# M5531 register map
File version: 1.0
Registers are 32-bit, read-write, reset 0x0 unless marked. A register's access mark holds for its fields unless they carry their own. Offsets are from the block's base; [hi:lo] are bit positions; {n}, {i} and the like mark numbered series; 'fields as' and 'values as' point back to an identical list.

## UTCPD — UTCPD Register Map
Base 0x4029B000
0x00 UTCPD_VID ro reset 0x416 — UTCPD Vendor ID Register
  [15:0] VID — UTCPD Vendor ID. Vendor identifier is used to identify the TCPC vendor, the VID is a unique 16-bit unsigned integer assigned by USB-IF to the Vendor.
0x04 UTCPD_PID (reset mask 0xFFFF0000) — UTCPD Product ID Register
  [15:0] PID — UTCPD Product ID. USB Product ID is used to identify the product
0x08 UTCPD_DID ro reset 0x1 — UTCPD Device ID Register
  [15:0] DID — UTCPD Device ID. USB Device ID is used to identify the release version of the product
0x0C UTCPD_TCREV ro reset 0x13 — UTCPD USB Type C Revision Register
  [7:0] TCREV — UTCPD USB Type C Revision. USB Type-C Cable and Connector Specification Revision 1.3
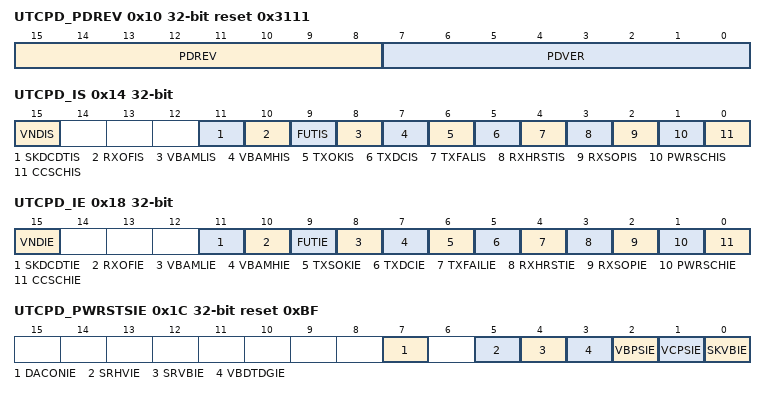
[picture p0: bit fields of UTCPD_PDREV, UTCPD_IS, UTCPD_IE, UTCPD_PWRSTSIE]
0x10 UTCPD_PDREV reset 0x3111 — UTCPD USB PD Revision Register
  [15:8] PDREV — UTCPD USB PD Revision. USB Power Delivery Specification revision 3.1
  [7:0] PDVER — UTCPD USB PD Vision. USB Power Delivery Specification Version 1.1
0x14 UTCPD_IS — UTCPD Interrupt Status Register
  [15] VNDIS — Vendor Define Event Detected. Note: It is cleared by software writing 1 into this bit.
    0=No vendor defined interrupt status has been detected; 1=A vendor defined interrupt status has been detected. Refer the vender defined interrupt status register
  [11] SKDCDTIS — VBUS Sink Disconnect Detected. This bit will be set when VBMONI (UTCPD_PWRCTL[6]) is enabled and VBUS voltage drop lower than SKVBDCTH (UTCPD_SKVBDCTH[9:0]). Note: It is cleared by software writing 1 into this bit.
    0=No disconnect detected; 1=A VBUS Sink disconnect threshold crossing has been detected
  [10] RXOFIS — Rx Buffer Overflow. Writing 1 to this register acknowledges the overflow. The overflow is cleared by writing 1 to RXSOPIS (UTCPD_IS[2])
    0=RX buffer is functioning properly; 1=RX buffer has overflowed
  [9] FUTIS — Fault Occur. Note: It is cleared by software writing 1 into this bit.
    0=No fault occurs; 1=A Fault has occurred. Read the FUT_STS register
  [8] VBAMLIS — VBUS Voltage Alarm Low. This bit will be set high when DSVBAM (UTCPD_PWRCTL[5]]) is low and VBUS voltage is lower than VBAML (UTCPD_VBAML[9:0]). Note: It is cleared by software writing 1 into this bit.
    0=No Low voltage alarm has occurred; 1=A Low voltage alarm has occurred
  [7] VBAMHIS — VBUS Voltage Alarm High. This bit will be set high when DSVBAM (UTCPD_PWRCTL[5]) is low and VBUS voltage is higher than VBAMH (UTCPD_VBAMH[9:0]). Note: It is cleared by software writing 1 into this bit.
    0=No high voltage alarm has occurred; 1=A high voltage alarm has occurred
  [6] TXOKIS — Transmit SOP* Message Successful. Note: It is cleared by software writing 1 into this bit.
    0=No TX SOP* transmit; 1=Reset or SOP* message transmission successful. GoodCRC response received on SOP* message transmission. Transmit SOP* message buffer registers are empty
  [5] TXDCIS — Transmit SOP* Message Discarded. Note: It is cleared by software writing 1 into this bit.
    0=No TX SOP discarded; 1=Reset or SOP* message transmission not sent due to incoming receive message. Transmit SOP* message buffer registers are empty
  [4] TXFALIS — Transmit SOP Fail. Note: It is cleared by software writing 1 into this bit.
    0=No Transmit SOP fail; 1=SOP* message transmission not successful, no GoodCRC response received on SOP* message transmission. Transmit SOP* message buffer registers are empty
  [3] RXHRSTIS — Received Hard Reset. Note: It is cleared by software writing 1 into this bit.
    0=No Hard reset Received; 1=Received Hard reset
  [2] RXSOPIS — Received SOP Message. UTCPD_RXBCNT being set to 0 does not set this bit. Note: It is cleared by software writing 1 into this bit.
    0=No SOP message Received; 1=Received SOP message
  [1] PWRSCHIS — Power Status Changed. Note: It is cleared by software writing 1 into this bit.
    0=Power status not change; 1=Power status changed
  [0] CCSCHIS — CC Status Changed. Note: It is cleared by software writing 1 into this bit.
    0=CC status not change; 1=CC status changed
0x18 UTCPD_IE — UTCPD Interrupt Enable Register
  [15] VNDIE — Vendor Define Event Detected Interrupt Enable
    0=Vendor define event detected interrupt Disabled; 1=Vendor define event detected interrup Enabled
  [11] SKDCDTIE — VBUS Sink Disconnect Detected Interrupt Enable
    0=VBUS Sink Disconnect Detected Interrupt Disabled; 1=VBUS Sink Disconnect Detected Interrupt Enabled
  [10] RXOFIE — Rx Buffer Overflow Interrupt Enable
    0=Rx Buffer Overflow Interrupt Disabled; 1=Rx Buffer Overflow Interrupt Enabled
  [9] FUTIE — Fault Occur Interrupt Enable
    0=Fault Occur Interrupt Disabled; 1=Fault Occur Interrupt Enabled
  [8] VBAMLIE — VBUS Voltage Alarm Low Interrupt Enable
    0=VBUS Voltage Alarm Low Interrupt Disabled; 1=VBUS Voltage Alarm Low Interrupt Enabled
  [7] VBAMHIE — VBUS Voltage Alarm High Interrupt Enable
    0=VBUS Voltage Alarm High Interrupt Disabled; 1=VBUS Voltage Alarm High Interrupt Enabled
  [6] TXSOKIE — Transmit SOP* Message Successful Interrupt Enable
    0=Transmit SOP* Message Successful Interrupt Disabled; 1=Transmit SOP* Message Successful Interrupt Enabled
  [5] TXDCIE — Transmit SOP* Message Discarded Interrupt Enable
    0=Transmit SOP* Message Discarded Interrupt Disabled; 1=Transmit SOP* Message Discarded Interrupt Enabled
  [4] TXFAILIE — Transmit SOP Fail Interrupt Enable
    0=Transmit SOP Fail Interrupt Disabled; 1=Transmit SOP Fail Interrupt Enabled
  [3] RXHRSTIE — Received Hard Reset Interrupt Enable
    0=Received Hard Reset Interrupt Disabled; 1=Received Hard Reset Interrupt Enabled
  [2] RXSOPIE — Received SOP Message Interrupt Enable
    0=Received SOP Message Interrupt Disabled; 1=Received SOP Message Interrupt Enabled
  [1] PWRSCHIE — Power Status Changed Interrupt Enable
    0=Power Status Changed Interrupt Disabled; 1=Power Status Changed Interrupt Enabled
  [0] CCSCHIE — CC Status Changed Interrupt Enable
    0=CC Status Changed Interrupt Disabled; 1=CC Status Changed Interrupt Enabled
0x1C UTCPD_PWRSTSIE reset 0xBF — UTCPD Power Status Interrupt Enable Register
  [7] DACONIE — Debug Accessory Connected Status Interrupt Enable
    0=Debug Accessory Connected Status Interrupt Disabled; 1=Debug Accessory Connected Status Interrupt Enabled
  [5] SRHVIE — Sourcing High Voltage Status Interrupt Enable
    0=Sourcing High Voltage Status Interrupt Disabled; 1=Sourcing High Voltage Status Interrupt Enabled
  [4] SRVBIE — Sourcing VBUS Status Interrupt Enable
    0=Sourcing VBUS Status Interrupt Disabled; 1=Sourcing VBUS Status Interrupt Enabled
  [3] VBDTDGIE — VBUS Detection Status Change Interrupt Enable
    0=VBUS Detection Status Change Interrupt Disabled; 1=VBUS Detection Status Change Interrupt Enabled
  [2] VBPSIE — VBUS Present Status Interrupt Enable
    0=VBUS Present Status Interrupt Disabled; 1=VBUS Present Status Interrupt Enabled
  [1] VCPSIE — VCONN Present Status Interrupt Enable
    0=VCONN Present Status Interrupt Disabled; 1=VCONN Present Status Interrupt Enabled
  [0] SKVBIE — Sinking VBUS Status Interrupt Enable
    0=Sinking VBUS Status Interrupt Disabled; 1=Sinking VBUS Status Interrupt Enabled
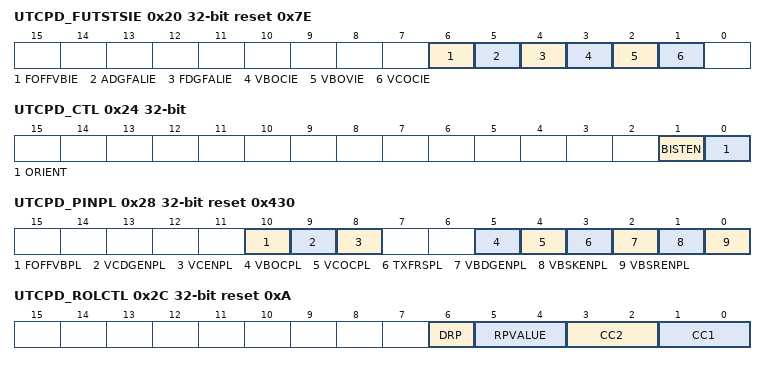
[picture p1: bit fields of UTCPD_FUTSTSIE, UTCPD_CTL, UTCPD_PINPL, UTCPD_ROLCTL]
0x20 UTCPD_FUTSTSIE reset 0x7E — UTCPD Fault Status Interrupt Enable Register
  [6] FOFFVBIE — Force Off VBUS Interrupt Enable
    0=Force Off VBUS Interrupt Disabled; 1=Force Off VBUS Interrupt Enabled
  [5] ADGFALIE — Auto Discharge Failed Interrupt Enable
    0=Auto Discharge Failed Interrupt Disabled; 1=Auto Discharge Failed Interrupt Enabled
  [4] FDGFALIE — Force Discharge Failed Interrupt Enable
    0=Force Discharge Failed Interrupt Disabled; 1=Force Discharge Failed Interrupt Enabled
  [3] VBOCIE — External VBUS OCP Fault Interrupt Enable
    0=External VBUS OCP Fault Interrupt Disabled; 1=External VBUS OCP Fault Interrupt Enabled
  [2] VBOVIE — Internal VBUS OVP Fault Interrupt Enable
    0=Internal VBUS OVP Fault Interrupt Disabled; 1=Internal VBUS OVP Fault Interrupt Enabled
  [1] VCOCIE — VCONN OCP Fault Interrupt Enable
    0=VCONN OCP Fault Interrupt Disabled; 1=VCONN OCP Fault Interrupt Enabled
0x24 UTCPD_CTL — UTCPD Control Register
  [1] BISTEN — BIST Test Mode. Setting this bit to 1 is intended to be used only when a USB compliance tester is using USB BIST Test Data to test the PHY layer of the UTCPD. The CPU should clear this bit when a detach is detected.
    0=Normal Operation; 1=BIST Test Mode
  [0] ORIENT — Plug Orientation communications if PD messaging is enabled.
    0=When VCONN is enabled, apply it to the CC2 pin. Monitor the CC1 pin for BMC communications if PD messaging is enabled; 1=When VCONN is enabled, apply it to the CC1 pin. Monitor the CC2 pin for BMC
0x28 UTCPD_PINPL reset 0x430 — UTCPD Pin Polarity Control Register
  [all] fields
    0=Low active; 1=High active
  [10] FOFFVBPL — Force Off VBUS event Polarity
  [9] VCDGENPL — VCONN Discharge Enable Polarity
  [8] VCENPL — VCONN Enable Polarity
  [5] VBOCPL — VBUS Overcurrent event Polarity
  [4] VCOCPL — VCONN Overcurrent event Polarity
  [3] TXFRSPL — Fast Role Swap TX Polarity
  [2] VBDGENPL — VBUS Discharge Enable Polarity. It is for Bleed Discharge Enable Polarity.
  [1] VBSKENPL — VBUS Sink Enable Polarity
  [0] VBSRENPL — VBUS Source Enable Polarity
0x2C UTCPD_ROLCTL reset 0xA — UTCPD Role Control Register
  [6] DRP — DRP. The UTCPD toggles CC1 CC2 after receiving LK4CON (UTCPD_CMD[5]) and until a connection is detected. Upon connection, the UTCPD shall resolve to either an Rp or Rd and report the CC1/CC2 State in the CC_STS register.
    0=No DRP; 1=DRP
  [5:4] RPVALUE
    0=Rp default; 1=Rp 1.5A; 2=Rp 3.0A
  [3:2] CC2
    1=Rp (Use Rp definition in RPVALUE); 2=Rd; 3=Open (Disconnect or don't care)
  [1:0] CC1
    2=Rd; 3=Open (Disconnect or don't care)
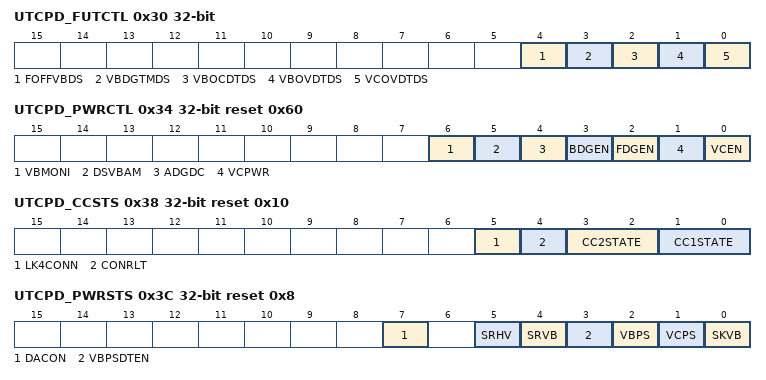
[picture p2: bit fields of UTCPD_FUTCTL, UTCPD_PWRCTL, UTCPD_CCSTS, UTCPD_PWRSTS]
0x30 UTCPD_FUTCTL — UTCPD Fault Control Register
  [4] FOFFVBDS — Force Off VBUS Disable
    0=Force off VBUS Enabled; 1=Force off VBUS Disabled
  [3] VBDGTMDS — VBUS Discharge Fault Detection Timer Disable. This enables the timer for both force discharge and auto discharge. No timer for bleed discharge. Once time-out, UTCPD will compare VBUS voltage with VSAFE0V or SP_DGTH, depends on setting of ADGDC and FDGEN.
    0=VBUS Discharge Fault Detection Timer enabled; 1=VBUS Discharge Fault Detection Timer disabled
  [2] VBOCDTDS — External VBUS Overcurrent Protection Fault Detect Disable
    0=External OCP circuit enabled; 1=External OCP circuit disabled
  [1] VBOVDTDS — Internal VBUS Over Voltage Protection Fault Detect Disable. Note: Internal VBUS over voltage protection means to use ADC to measure VBUS voltage.
    0=Internal OVP circuit enabled; 1=Internal OVP circuit disabled
  [0] VCOVDTDS — External VCONN Overcurrent Fault Detect Disable
    0=External VCONN OCP circuit enabled; 1=External VCONN OCP circuit disabled
0x34 UTCPD_PWRCTL reset 0x60 — UTCPD Power Control Register
  [6] VBMONI — VBUS Voltage Monitor Enable. Controls VBUS voltage Monitoring. UTCPD_VBVOL shall report all zeroes if disabled.
    0=VBUS Voltage Monitoring is enabled; 1=VBUS Voltage Monitoring is disabled (default)
  [5] DSVBAM — Disable VBUS Voltage Alarms
    0=VBUS Voltage Alarms Power status reporting is enabled; 1=VBUS Voltage Alarms Power status reporting is disabled (default)
  [4] ADGDC — Auto Discharge Disconnect . Setting this bit in a Source UTCPD triggers the following actions upon a disconnect detection: 1. Disable sourcing power over VBUS. 2. VBUS discharge. Sourcing power over VBUS shall be disabled before or at the same time as starting VBUS discharge. Setting this bit in a Sink UTCPD triggers the following action upon a disconnect detection: 1. VBUS discharge. The UTCPD shall automatically disable discharge (without clearing this bit) once the voltage on VBUS is below vSafe0V (max). UTCPD shall not re-apply discharge circuit if VBUS rises above vSafe0V. This bit will only be cleared by CPU.
    0=The UTCPD shall not automatically discharge VBUS based on VBUS voltage (default); 1=The UTCPD shall automatically discharge when disconnect detected
  [3] BDGEN — Enable Bleed Discharge. Bleed Discharge is a low current discharge to provide a minimum load current if needed. 10K Ohms or 2mA recommended. Bleed discharge is used for sink only. This bit will only be cleared by CPU.
    0=Disable bleed discharge (default); 1=Enable bleed discharge of VBUS
  [2] FDGEN — Enable Force Discharge. Force discharge is used for source only. This bit will only be cleared by CPU.
    0=Disable forced discharge (default); 1=Enable forced discharge of VBUS
  [1] VCPWR — VCONN Power Supported
    0=UTCPD delivers at least 1W on VCONN; 1=UTCPD delivers at least the power indicated in CPVCPWR (UTCPD_DVCAP2[3:1])
  [0] VCEN — Enable VCONN
    0=Disable VCONN Source (default); 1=Enable VCONN Source to CC
0x38 UTCPD_CCSTS ro reset 0x10 — UTCPD CC Status Register
  [5] LK4CONN — Looking for Connection
    0=UTCPD is not actively looking for a connection. A transition from '1' to '0' indicates a potential connection has been found; 1=UTCPD is looking for a connection (toggling as a DRP or looking for a connection as Sink/Source only condition)
  [4] CONRLT — Connect Result (read only)
    0=the UTCPD is presenting Rp; 1=the UTCPD is presenting Rd
  [3:2] CC2STATE
    0=SRC.Open (Open, Rp). SNK.Open (Below maximum vRa); 1=SRC.Ra (below maximum vRa). SNK.Default (Above minimum vRd-Connect); 2=SRC.Rd (within the vRd range). SNK.Power1.5 (Above minimum vRd-Connect) Detects Rp 1.5A; 3=reserved. SNK.Power3.0 (Above minimum vRd-Connect) Detects Rp 3.0A
  [1:0] CC1STATE
    values as CC2STATE
0x3C UTCPD_PWRSTS ro reset 0x8 — UTCPD Power Status Register
  [7] DACON — Debug Accessory Connected
    0=No Debug Accessory connected (default); 1=Debug Accessory connected
  [5] SRHV — Sourcing High Voltage. This bit does not control the power path, it just provides a monitor of the status. This bit is asserted as long as the UTCPD is sourcing nondefault voltage over VBUS (i.e. not VSAFE5V) as a response to CPU writing 0x88 to CMD (Source VBUS High Voltage)
    0=VSAFE5V; 1=Higher Voltage
  [4] SRVB — Sourcing VBUS. This bit does not control the path, just provides a monitor of the status.
    0=Sourcing VBUS Disabled; 1=Sourcing VBUS Enabled
  [3] VBPSDTEN — VBUS Present Detection Enabled
    0=VBUS Present Detection Disabled; 1=VBUS Present Detection Enabled (default)
  [2] VBPS — VBUS Present. The UTCPD shall report VBUS present when UTCPD detects VBUS rises above 4V. The UTCPD shall report VBUS is not present when UTCPD detects VBUS falls below 3.5V.
    0=VBUS Disconnected; 1=VBUS Connected
  [1] VCPS — VCONN Present. If VCEN (UTCPD_PWRCTL[0])] is disabled VCONN Present should be set to 0.
    0=VCONN is not present; 1=This bit is asserted when VCONN present CC1 or CC2. Threshold is fixed at 2.4V
  [0] SKVB — Sinking VBUS
    0=Sink is Disconnected (Default); 1=UTCPD is sinking VBUS to the system load
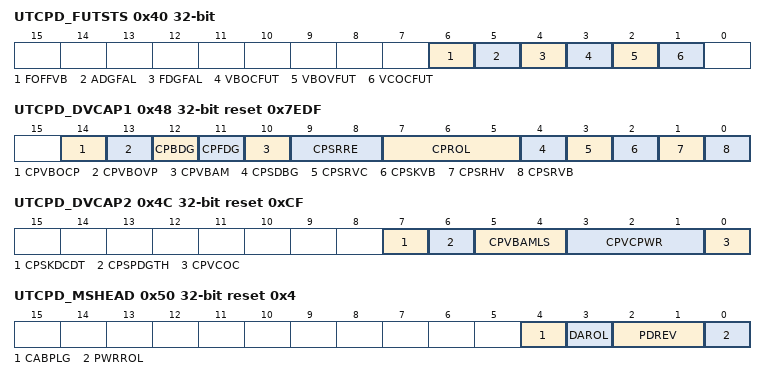
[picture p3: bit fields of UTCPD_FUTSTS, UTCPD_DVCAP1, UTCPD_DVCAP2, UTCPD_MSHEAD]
0x40 UTCPD_FUTSTS ro — UTCPD Fault Status Register
  [6] FOFFVB — Force Off VBUS. The UTCPD has disconnected VBUS due to external inputs (EINT0 ~ EINT5)
    0=No Fault Detected, no action (default and not supported); 1=VBUS Source/Sink has been forced off due to external fault
  [5] ADGFAL — Auto Discharge Failed. If ADGDC (UTCPD_PWRCTL[4]) is set, the UTCPD shall report discharge fails if VBUS is not below vSafe0V within tSafe0V
    0=No discharge failure; 1=Discharge commanded by the TCPM failed
  [4] FDGFAL — Force Discharge Failed. If FDGEN (UTCPD_PWRCTL[2]) is set, the UTCPD shall report a discharge fails if VBUS is not below vSafe0V within tSafe0V.
    values as ADGFAL
  [3] VBOCFUT — VBUS Overcurrent Protection Fault
    0=Not in an overcurrent protection state; 1=Overcurrent fault latched
  [2] VBOVFUT — VBUS Over Voltage Protection Fault
    0=No Fault detected; 1=Over-voltage fault latched
  [1] VCOCFUT — VCONN Overcurrent Protection Fault
    values as VBOCFUT
0x44 UTCPD_CMD — UTCPD Command Register
  [7:0] CMD — Command Set. Others: Reserved. The Command is issued by the CPU. The Command is cleared by the UTCPD after being acted upon. It always read as 0.
    34=Disable VBUS Detect; 51=Enable VBUS Detect; 68=Disable Sink VBUS; 102=Disable Source VBUS; 119=Enable Source VBUS 5V; 136=Source VBUS High Voltage; 170=RxOneMore
0x48 UTCPD_DVCAP1 reset 0x7EDF — UTCPD Device Capabilities 1 Register
  [14] CPVBOCP — VBUS OCP Reporting
    0=VBUS OCP is not reported; 1=VBUS OCP is reported
  [13] CPVBOVP — VBUS OVP Reporting
    0=VBUS OVP is not reported; 1=VBUS OVP is reported
  [12] CPBDG — Bleed Discharge
    0=No Bleed Discharge implemented; 1=Bleed Discharge is implemented
  [11] CPFDG — Force Discharge
    0=No Force Discharge implemented; 1=Force Discharge is implemented
  [10] CPVBAM — VBUS Measurement and Alarm Capable
    0=No VBUS voltage measurement nor VBUS Alarms; 1=VBUS voltage measurement and VBUS Alarms
  [9:8] CPSRRE — Source Resistor Supported
    0=Rp default only; 1=Rp 1.5A and default; 2=Rp 3.0A, 1.5A, and default
  [7:5] CPROL — Roles Supported
    0=USB Type-C Port Manager can configure the Port as Source only or Sink only (not DRP); 1=Source only; 2=Sink only; 3=Sink with accessory support; 4=DRP only; 5=Source, Sink, DRP, Adapter/Cable all supported; 6=Source, Sink, DRP; 7=Not valid
  [4] CPSDBG — SOP'_DBG/SOP'_DBG Support
    0=All SOP* except SOP'_DBG/SOP'_DBG; 1=All SOP* messages are supported
  [3] CPSRVC — Source VCONN
    0=UTCPD is not capable of switching VCONN; 1=UTCPD is capable of switching VCONN
  [2] CPSKVB — Sink VBUS
    0=UTCPD is not capable controlling the sink path to the system load; 1=UTCPD is capable of controlling the sink path to the system load
  [1] CPSRHV — Source High Voltage VBUS
    0=UTCPD is not capable of controlling the source high voltage path to VBUS; 1=UTCPD is capable of controlling the source high voltage path to VBUS
  [0] CPSRVB — Source VBUS
    0=TCPC is not capable of controlling the source path to VBUS; 1=TCPC is capable of controlling the source path to VBUS
0x4C UTCPD_DVCAP2 reset 0xCF — UTCPD Device Capabilities 2 Register
  [7] CPSKDCDT — Sink Disconnect Detection
    0=UTCPD_SKVBDCTH not implemented; 1=UTCPD_SKVBDCTH implemented
  [6] CPSPDGTH — Stop Discharge Threshold
    0=UTCPD_SPDGTH not implemented; 1=UTCPD_SPDGTH implemented
  [5:4] CPVBAMLS — VBUS Voltage Alarm LSB
    0=UTCPD has 25mV LSB for its voltage alarm and uses all 10 bits in
  [3:1] CPVCPWR — VCONN Power Supported
    0=1.0W; 1=1.5W; 2=2.0W; {v}={v}W (v=3..6); 7=External
  [0] CPVCOC — VCONN Overcurrent Fault Capable
    0=UTCPD is not capable of detecting a Vconn fault; 1=UTCPD is capable of detecting a Vconn fault
0x50 UTCPD_MSHEAD reset 0x4 — UTCPD Message Header Info Register
  [4] CABPLG — Cable Plug
    0=Message originated from Source, Sink, or DRP; 1=Message originated from a Cable Plug
  [3] DAROL — Data Role
    0=UFP; 1=DFP
  [2:1] PDREV — USB PD Specification Revision
    0=Revision 1.0; 1=Revision 2.0; 2=Revision 3.0; 3=Revision 3.1
  [0] PWRROL — Power Role
    0=Sink; 1=Source
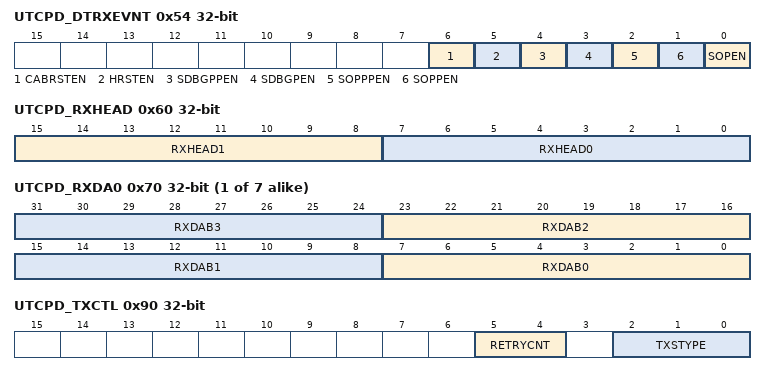
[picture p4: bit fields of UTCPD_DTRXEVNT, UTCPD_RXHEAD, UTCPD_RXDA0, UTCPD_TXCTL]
0x54 UTCPD_DTRXEVNT — UTCPD Enable Detect RX Event Register
  [6] CABRSTEN — Enable Cable Reset
    0=UTCPD does not detect Cable Reset signaling (default); 1=UTCPD detects Cable Reset signaling
  [5] HRSTEN — Enable Hard Reset
    0=UTCPD does not detect Hard Reset signaling (default); 1=UTCPD detects Hard Reset signaling
  [4] SDBGPPEN — Enable SOP_DBG'' message
    0=UTCPD does not detect SOP_DBG'' message (default); 1=UTCPD detects SOP_DBG'' message
  [3] SDBGPEN — Enable SOP_DBG' message
    0=UTCPD does not detect SOP_DBG' message (default); 1=UTCPD detects SOP_DBG' message
  [2] SOPPPEN — Enable SOP'' message
    0=UTCPD does not detect SOP'' message (default); 1=UTCPD detects SOP'' message
  [1] SOPPEN — Enable SOP' message
    0=UTCPD does not detect SOP' message (default); 1=UTCPD detects SOP' message
  [0] SOPEN — Enable SOP message
    0=UTCPD does not detect SOP message (default); 1=UTCPD detects SOP message
0x58 UTCPD_RXBCNT ro — UTCPD RX Byte Count Register
  [7:0] RXBCNT — Receive Byte Count. Indicates number of bytes in this register that are not stale. CPU should read the first RXBCNT bytes in this register. This is the number of bytes in the UTCPD_RXDAx plus three (for the RXFTYPE and RXHEAD). The UTCPD shall clear the UTCPD_DTRXEVNT and the UTCPD_RXBCNT register to disable the PD message passing when CPU writes the UTCPD_TXCTL register requesting a Hard Reset.
0x5C UTCPD_RXFTYPE ro — UTCPD Received Frame Type Register
  [2:0] RXFTYPE — Received Frame Type. All others are reserved.
    0=Received SOP; 1=Received SOP'; 2=Received SOP''; 3=Received SOP_DBG'; 4=Received SOP_DBG''; 6=Received Cable Reset
0x60 UTCPD_RXHEAD ro — UTCPD Received Header Data Register
  [15:8] RXHEAD1 — USB PD message header byte 1
  [7:0] RXHEAD0 — USB PD message header byte 0
{0x70+4i} UTCPD_RXDA{i} ro (i=0..6) — UTCPD Received Data{i} Register
  [8n+7:8n] RXDAB{n} (n=0..3) — USB PD Received Datax byte {n}
0x90 UTCPD_TXCTL — UTCPD TX Control Register
  [5:4] RETRYCNT — Retry Counter
    0=No message retry is required; 1=Automatically retry message transmission once; 2=Automatically retry message transmission twice; 3=Automatically retry message transmission three times
  [2:0] TXSTYPE — Transmit SOP* message. The UTCPD shall ignore the Retry Counter bits when transmitting a Hard Reset, Cable Reset, or BIST Carrier
    0=Transmit SOP; 1=Transmit SOP'; 2=Transmit SOP''; 3=Transmit SOP_DBG'; 4=Transmit SOP_DBG''; 5=Transmit Hard Reset; 6=Transmit Cable Reset; 7=Transmit BIST Carrier Mode 2
0x94 UTCPD_TXBCNT — UTCPD TX Byte Count Register
  [7:0] TXBCNT — Transmit Byte Count. This is the number of bytes in the UTCPD_TXDA plus two (for the TXHEAD). If a previous transmit request has not yet completed when TX_CTL is written requesting a Hard Reset, the UTCPD shall assert the Transmission Discarded bit(TXDCIS (UTCPD_IS[5])). The UTCPD shall assert both TXOKIS (UTCPD_IS[6]) and TXFALIS (UTCPD_IS[4]) after it completes the sending of a Hard Reset.
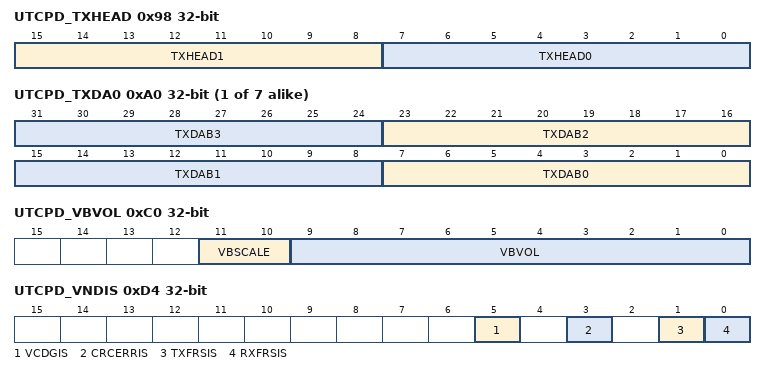
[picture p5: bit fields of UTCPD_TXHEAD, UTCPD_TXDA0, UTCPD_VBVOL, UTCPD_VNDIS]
0x98 UTCPD_TXHEAD — UTCPD TX Header Data Register
  [15:8] TXHEAD1 — Transmit Header Byte 1
  [7:0] TXHEAD0 — Transmit Header Byte 0
{0xA0+4i} UTCPD_TXDA{i} (i=0..6) — UTCPD Transmit Data{i} Register
  [8n+7:8n] TXDAB{n} (n=0..3) — USB PD Transmit Datax byte {n}
0xC0 UTCPD_VBVOL — UTCPD VBUS Voltage Register
  [11:10] VBSCALE — VBUS Scale Factor
    0=VBUS measurement not scaled; 1=VBUS measurement divided by 2; 2=VBUS measurement divided by 4
  [9:0] VBVOL — VBUS voltage measurement. 10-bit measurement of (VBUS / Scale Factor). These bits is read only. CPU multiplies this value by the scale factor to obtain the voltage measurement. Voltages greater than or equal to 4V shall meet +/-2% absolute value or +/- 50mV, whichever is greater. The LSB is 25mV.
0xC4 UTCPD_SKVBDCTH reset 0x8C — UTCPD VBUS Sink disconnect threshold Register
  [9:0] SKVBDCTH — Sink VBUS disconnect threshold. 10-bit for voltage threshold with 25mV LSB. (Default 3.5V). A value of zero disables this threshold.
0xC8 UTCPD_SPDGTH reset 0x20 — UTCPD VBUS Stop Discharge threshold Register
  [9:0] SPDGTH — VBUS Stop Force Discharge Threshold. This value is used as a threshold hold for force discharge fail. The default is 0.8V. . The CPU writes to this register to set the threshold at which a Source shall stop the Forced Discharge circuit when FDGEN (UTCPD_PWRCTL[2]) is 1.
0xCC UTCPD_VBAMH — UTCPD VBUS voltage high alarm threshold Register
  [9:0] VBAMH — VBUS voltage high Alarm threshold register
0xD0 UTCPD_VBAML — UTCPD VBUS voltage low alarm threshold Register
  [9:0] VBAML — VBUS voltage low Alarm threshold register
0xD4 UTCPD_VNDIS — UTCPD Vendor defined Interrupt Status Register
  [5] VCDGIS — VCONN Discharge Interrupt Status
  [3] CRCERRIS — CRC Error Interrupt Status
    0=Cleared; 1=The event has been detected
  [1] TXFRSIS — Fast Role Swap TX Interrupt Status
    0=Cleared; 1=The event has been detected
  [0] RXFRSIS — Fast Role Swap RX Interrupt Status
    0=Cleared; 1=The event has been detected
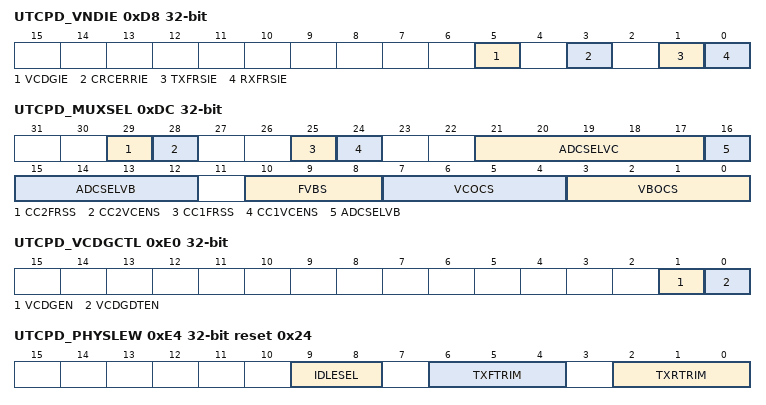
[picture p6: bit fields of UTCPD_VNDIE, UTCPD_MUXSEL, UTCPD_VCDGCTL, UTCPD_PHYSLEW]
0xD8 UTCPD_VNDIE — UTCPD Vendor defined Interrupt Enable Register
  [5] VCDGIE — VCONN Discharge Interrupt Enable
    0=VCOON discharge interrupt Disabled; 1=VCOON discharge interrupt Enabled
  [3] CRCERRIE — CRC Error Interrupt Enable
    0=CRC error interrupt Disabled; 1=CRC error interrupt Enabled
  [1] TXFRSIE — Fast Role Swap TX Interrupt Enable
    0=Fast role swap TX interrupt Disabled; 1=Fast role swap TX interrupt Enabled
  [0] RXFRSIE — Fast Role Swap RX Interrupt Enable
    0=Fast role swap RX interrupt Disabled; 1=Fast role swap RX interrupt Enabled
0xDC UTCPD_MUXSEL — UTCPD Mux Select Register
  [29] CC2FRSS — CC2 VCONN Fast Role Swap Select
    0=Merged CC1 and CC2 Fast Role Swap signal; 1=CC2 VCONN discharge signal
  [28] CC2VCENS — CC2 VCONN Enable Select
    0=Merged CC1 and CC2 VCONN enable signal; 1=CC2 VCONN enable signal
  [25] CC1FRSS — CC1 VCONN Fast Role Swap Select
    0=Merged CC1 and CC2 VCONN Fast Role Swap signal; 1=CC1 VCONN Fast Role Swap signal
  [24] CC1VCENS — CC1 VCONN Enable Select
    0=Merged CC1 and CC2 VCONN enable signal; 1=CC1 VCONN enable signal
  [21:17] ADCSELVC — ADC Channel Select for VCONN. ADC result will be latched into VCVOL register once ADCCSELVC matches ADC_CHSEL and ADC finishes.
  [16:12] ADCSELVB — ADC Channel Select for VBUS. ADC result will be latched into VBVOL register once ADCCSELVB matches ADC_CHSEL and ADC finishes.
  [10:8] FVBS — Force off VBUS Select
    0=ENIT0; 1=EINT1; 2=EINT2; 3=ENIT3; 4=EINT4; 5=EINT5
  [7:4] VCOCS — VCONN Overcurrent Source Select. Note: For ACMP, the VCOCPL (PINPL[10]) shall be set as 1.
    {v}=EINT{v} (v=0..3); 4=ADCMPF1; {v}=ACMP{v-5} (v=5..8)
  [3:0] VBOCS — VBUS Overcurrent Source Select. Note: For ACMP, the VBOCPL (PINPL[5]) shall be set as 1.
    {v}=EINT{v} (v=0..3); 4=ADCMPF0; {v}=ACMP{v-5} (v=5..8)
0xE0 UTCPD_VCDGCTL — UTCPD VCONN Discharge Control Register
  [1] VCDGEN — VCONN Discharge Enable
    0=Disabled; 1=Enabled
  [0] VCDGDTEN — VCONN Discharge Detect Enable
    0=Disabled; 1=Enabled
0xE4 UTCPD_PHYSLEW reset 0x24 — UTCPD PHY Slew Rate Control Register
  [9:8] IDLESEL — Bus Idle Select. Only after bus idle, the de-bounce circuit starts.
    0=Digital bus no transaction over 12us; 1=Digital and analog bus no transaction over 12us; 2=Analog bus no transaction over 12us; 3=CC pins no activity
  [6:4] TXFTRIM — TX Trim Falling slew rate. It is for BMC eye diagram. Trim PHY TX falling slew rate. (from ROMMAP)
  [2:0] TXRTRIM — TX Trim Rising slew rate. It is for BMC eye diagram. Trim PHY TX Rising slew rate (from ROMMAP)
0xE8 UTCPD_ADGTM reset 0x64 — UTCPD Auto Discharge Time Register
  [7:0] ADGTM — Auto Discharge time
0xEC UTCPD_VSAFE0V — UTCPD Auto Discharge VSAFE0V Register
  [9:0] VSAFE0V — Set the vSafe0V voltage level.
0xF0 UTCPD_VSAFE5V reset 0xC8
  [9:0] VSAFE5V — Set the vSafe5V voltage level. For fast role swap voltage comparison.
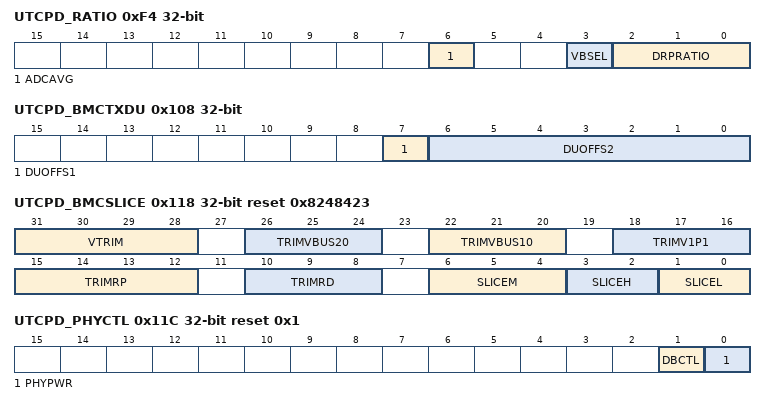
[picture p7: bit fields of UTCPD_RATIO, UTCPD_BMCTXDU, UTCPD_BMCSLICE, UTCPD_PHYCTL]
0xF4 UTCPD_RATIO — UTCPD DRP Toggle Ratio Register
  [6] ADCAVG — ADC moving average enable. If enable this bit, average the ADC value for 4 times
  [3] VBSEL — VBUS_VOLTAGE_SEL. Select comparing value (vbus_voltage_s) during vbus discharge determines to stop discharging or not.
    0=VBUS voltage value from ADC only when VBMONI (UTCPD_PWRCT[6]) is 1; 1=VBUS voltage value from ADC
  [2:0] DRPRATIO — The percent of time that a DRP shall advertise source sink during tDRP
    0=50:50 (Sink : Source); 1=40:60 (Sink : Source); 2=30:70 (Sink : Source); 5=60:40 (Sink : Source); 6=70:30 (Sink: Source)
0xF8 UTCPD_INTFRAME reset 0x19 — UTCPD Inter-Frame Time Register
  [7:0] INTFRAME — USB PD Inter frame gap. Each unit time: 83ns (12 MHz RC)
0xFC UTCPD_VBOVTH reset 0x3FF — UTCPD VBUS Over Voltage Threshold Register
  [9:0] VBOVTH — VBUS Over Voltage Threshold. This value defines the VBUS over voltage threshold. 10-bit for voltage threshold with 25mV LSB.
0x100 UTCPD_VNDINIT reset 0x64 — UTCPD Vendor Initial Register
  [6:4] DVCAPDEF — Device Capability Default Setting
0x104 UTCPD_BMCTXBP reset 0x27 — UTCPD BMC TX Bit Period Register
  [7:0] BMCTXBP — BMC Tx bit period. It's for BMC eye diagram.
0x108 UTCPD_BMCTXDU — UTCPD BMC TX Duty Register
  [7] DUOFFS1 — BMC Tx duty offset parameter 1. It's for BMC eye diagram.
    0=Increase duty offset?. (+); 1=Decrease duty offset?. (-)
  [6:0] DUOFFS2 — BMC Tx duty offset parameter 2. It's for BMC eye diagram. Offset count value.
0x10C UTCPD_VCPSVOL reset 0x60 — VCONN Present Voltage Register
  [9:0] VCPSVOL — VCONN Present voltage
0x110 UTCPD_VCUV reset 0x20 — VCONN Under Voltage Register
  [9:0] VCUV — VCONN under voltage comparator
0x118 UTCPD_BMCSLICE reset 0x8248423 — UTCPD BMC SLICE Control Register
  [31:28] VTRIM — Reference Voltage TRIM setting for TCPD PHY macro
  [26:24] TRIMVBUS20
  [22:20] TRIMVBUS10
  [18:16] TRIMV1P1
  [15:12] TRIMRP
  [10:8] TRIMRD
  [6:4] SLICEM — TX Slice Middle Level Control. Middle level slice control (The LSB is 2mV.)
    0=0.48V; 4=0.56V (Default); 7=0.62V
  [3:2] SLICEH — TX Slice High Level Control. High level slice control (The LSB is 2mV.)
    0=0.84V (Default); 1=0.86V; 2=0.88V; 3=0.9V
  [1:0] SLICEL — TX Slice Low Level Control. Low level slice control (The LSB is 2mV.)
    0=0.18V; 1=0.2V; 2=0.22V; 3=0.24V (Default)
0x11C UTCPD_PHYCTL reset 0x1 — UTCPD PHY Power Control Register
  [1] DBCTL — Dead Battery control
    0=Dead Battery circuit control internal Rd/Rp; 1=Role Control Register control internal Rd/Rp
  [0] PHYPWR — Analog PHY Power
    0=Power down PHY; 1=Enable PHY
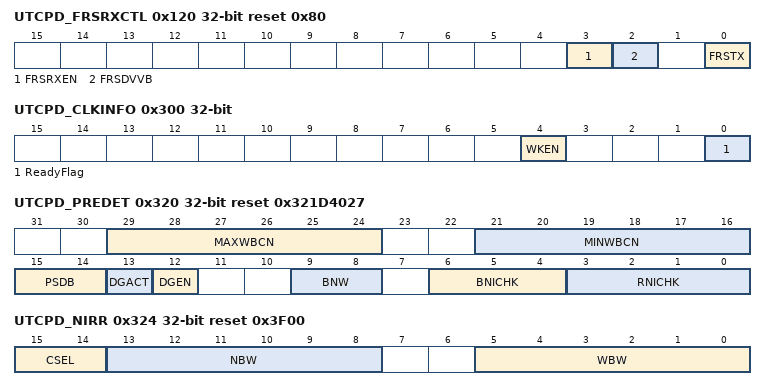
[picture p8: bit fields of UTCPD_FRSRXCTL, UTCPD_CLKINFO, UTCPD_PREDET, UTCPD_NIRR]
0x120 UTCPD_FRSRXCTL reset 0x80 — UTCPD CC Fast Swap RX Control Register
  [3] FRSRXEN — CC receive fast swap Rx Enable
    0=CC receive fast swap RX Disabled; 1=CC receive fast swap RX Enabled
  [2] FRSDVVB — CC receive fast swap and auto drive Source VBUS
    0=CC receive fast swap and auto drive Souce Disabled; 1=CC receive fast swap and auto drive Souce Enabled
  [0] FRSTX — CC transmitter fast swap signal. Pulse width is 85us.
0x124 UTCPD_VCVOL ro — UTCPD VCONN Voltage Measurement Register
  [9:0] VCVOL — VCONN Voltage Measurement. The LSB is 25mV
0x300 UTCPD_CLKINFO — UTCPD Clock Information Register
  [4] WKEN — Wakeup enable
    0=UTCPD wakeup function Disabled; 1=UTCPD wakeup function Enabled
  [0] ReadyFlag — RC32K domain ready flag Check if the register value is loaded to RC32K domain by reading this flag
    0=The RC32K signal is not ready; 1=The RC32K signal is ready
0x320 UTCPD_PREDET reset 0x321D4027 — UTCPD Preamble Detect Register
  [29:24] MAXWBCN — Maximun Width Bit Counter Number. Define the maximun width of one bit counter number among preamble period. If the counter of one bit width is over this value, this case path will be ignore to juge the bit counter number. Note: The default value is the bit clock counter of minimun bit rate frequency (270K) minus 10%.
  [21:16] MINWBCN — Minimum Width Bit Counter Number. Define the minuimun width of one bit counter number among preamble period. If the counter of one bit width is less than this value, this case path will be ignore to juge the bit counter number. Note: The default value is the bit clock counter of maxmun bit rate frequency (330K) plus 10%.
  [15:14] PSDB — Preamble Start Detect Bit
    0=Round start after first 3 bits be detected; 1=Round start after first 5 bits be detected; 2=Round start after first 6 bits be detected; 3=Round start after first 7 bits be detected
  [13] DGACT — Analog Macro Activity Signal Source from Deglitch Circuit
    0=Analog macro activity signal source from deglitch circuit Disabled; 1=Analog macro activity signal source from deglitch circuit Enabled
  [12] DGEN — Analog Macro Deglitch circuit Enable
    0=Analog macro deglitch circuit Disabled; 1=Analog macro 3 slices comparator deglitch circuit Enabled
  [9:8] BNW — Bit Number Wait for next Round
    {v}=The wait bit number for next round is {v+1} bits (v=0..3)
  [6:4] BNICHK — Bit Number for Noise Immunity Check each Round
    {v}=The detected bit number of one round equal to {v+3} bits (v=0..5)
  [3:0] RNICHK — Round of Noise Immunity Check
    0=Noise immunity optimize Disabled; 1=The detect is one round; 2=The detect is two rounds; 3=The detect is three rounds; 4=The detect is four rounds; 5=The detect is five rounds; 6=The detect is six rounds; 7=The detect is seven rounds; 8=The detect is eight round; 9=The detect is nini rounds; 10=The detect is ten rounds; 11=The detect is eleven rounds; 12=The detect is twelve rounds; 13=The detect is thirteen rounds; 14=The detect is fourteen rounds; 15=The detect is fifteen rounds
0x324 UTCPD_NIRR ro reset 0x3F00 — UTCPD Noise Immunity Record Register
  [15:14] CSEL — Case Selection (Read Only). The field indicates the selected case condition.
    0=The case 0; 1=The case 1; 2=The case 2
  [13:8] NBW — Narrow Bit Width (Read Only). The field indicates the narrow bit width (based on 12M).
  [5:0] WBW — Wide Bit Width (Read Only). The field indicates the wide bit width (based on 12M).
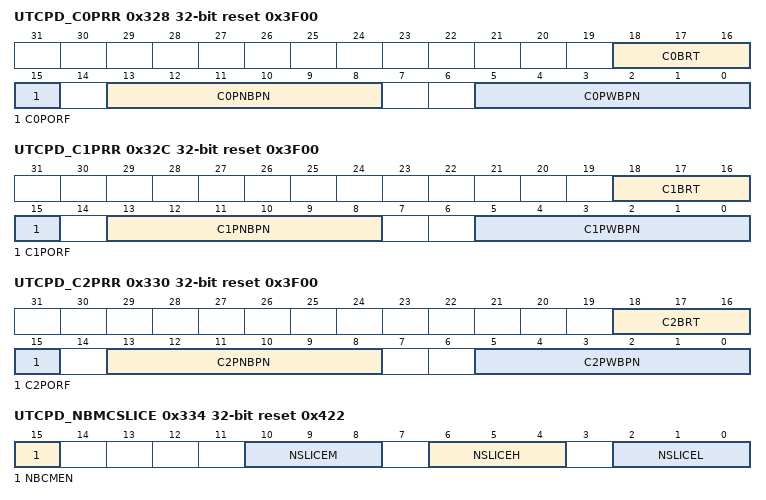
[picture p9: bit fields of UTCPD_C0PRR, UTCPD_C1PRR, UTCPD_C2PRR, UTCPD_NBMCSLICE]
0x328 UTCPD_C0PRR ro reset 0x3F00 — UTCPD Case 0 Path Record Register
  [18:16] C0BRT — Case 0 Path Best Round Times. The field indicates the best round times of bit width detection. Note: It is cleared in next preamble start or write 1.
  [15] C0PORF — Case 0 Path Out of Range Flag. Note: It is cleared in next preamble start or write 1.
    0=Case 0 isn't out of range; 1=Case 0 is out of range
  [13:8] C0PNBPN — Case 0 Path Narrow Bit Period Number (Read Only). The field indicates the final narrow bit clcok number based 12M. If the RNICHK (UTCPD_PREDET[2:0]) is 3'b000, the default value is 0x3F. Note: It is cleared in next preamble start or write 1.
  [5:0] C0PWBPN — Case 0 Path Wide Bit Period Number (Read Only). The field indicates the final width bit clock number based 12M clock. Note: It is cleared in next preamble start or write 1.
0x32C UTCPD_C1PRR ro reset 0x3F00 — UTCPD Case 1 Path Record Register
  [18:16] C1BRT — Case 1 Path Best Round bnTimes. The field indicates the best round times of bit width detection. Note: It is cleared in next preamble start or write 1.
  [15] C1PORF — Case 1 Path Out of Range Flag. Note: It is cleared in next preamble start or write 1.
    0=Case 1 isn't out of range; 1=Case 1 is out of range
  [13:8] C1PNBPN — Case 1 Path Narrow Bit Period Number (Read Only). The field indicates the final narrow bit clcok number based 12M. Note: It is cleared in next preamble start or write 1.
  [5:0] C1PWBPN — Case 1 Path Wide Bit Period Number (Read Only). The field indicates the final width bit clock number based 12M clock. Note: It is cleared in next preamble start or write 1.
0x330 UTCPD_C2PRR ro reset 0x3F00 — UTCPD Case 2 Path Record Register
  [18:16] C2BRT — Case 2 Path Best Round Times. The field indicates the best round times of bit width detection. Note: It is cleared in next preamble start or write 1.
  [15] C2PORF — Case 2 Path Out of Range Flag. Note: It is cleared in next preamble start or write 1.
    0=Case 2 isn't out of range; 1=Case 2 is out of range
  [13:8] C2PNBPN — Case 2 Path Narrow Bit Period Number (Read Only). The field indicates the final narrow bit clcok number based 12M. Note: It is cleared in next preamble start or write 1.
  [5:0] C2PWBPN — Case 2 Path Wide Bit Period Number (Read Only). The field indicates the final width bit clock number based 12M clock. Note: It is cleared in next preamble start or write 1.
0x334 UTCPD_NBMCSLICE reset 0x422 — UTCPD New BMC SLICE Control Register
  [15] NBCMEN — New BMC Trim Value Control Enable
    0=The trim value of BMC is compatiable with UTCPD_BMCSLICE; 1=New BMC trim value in this regsiter bit field
  [10:8] NSLICEM — New TX Slice Middle Level Control. Middle level slice control (The LSB is 20mV.)
    0=0.48V; 1=0.50V; 2=0.52V; 3=0.54V; 4=0.56V (Default); 5=0.58V; 6=0.60V; 7=0.62V
  [6:4] NSLICEH — New TX Slice High Level Control. High level slice control (The LSB is 20mV.)
    0=0.80V; 1=0.82V; 2=0.84V (Default); 3=0.86V; 4=0.88V; 5=0.90V; 6=0.92V; 7=0.94V
  [2:0] NSLICEL — New TX Slice Low Level Control. Low level slice control (The LSB is 20mV.)
    0=0.14V; 1=0.16V; 2=0.18V (Default); 3=0.20V; 4=0.22V; 5=0.24V; 6=0.26V; 7=0.28V
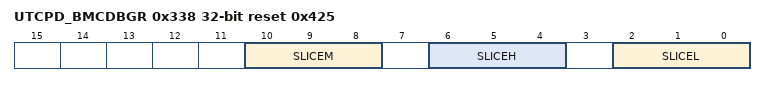
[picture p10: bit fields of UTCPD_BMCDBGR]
0x338 UTCPD_BMCDBGR ro reset 0x425 — UTCPD BMC SLICE Value Debug Register
  [10:8] SLICEM — TX Slice Middle Level Control (Read Only). Middle level slice control (The LSB is 20mV.). Note: For FPGA Debug and Read Only.
    values as UTCPD_NBMCSLICE.NSLICEM
  [6:4] SLICEH — TX Slice High Level Control (Read Only). High level slice control (The LSB is 20mV.). Note: For FPGA Debug and Read Only.
    values as UTCPD_NBMCSLICE.NSLICEH
  [2:0] SLICEL — TX Slice Low Level Control (Read Only). Low level slice control (The LSB is 20mV.). Note: For FPGA Debug and Read Only.
    values as UTCPD_NBMCSLICE.NSLICEL
